# cslr_rac_cfg register map
Vendor: Texas Instruments
Peripheral module from a debugger description file.
Registers are 32-bit, access not given, reset 0x0 unless marked. A register's access mark holds for its fields unless they carry their own. Offsets are as the file gives them; lines under a group give offsets from that group; [hi:lo] are bit positions; {n}, {i} and the like mark numbered series; 'fields as' and 'values as' point back to an identical list; <NAME> marks a mode.

## RAC_CFG — Uplink Chip-Rate Decoder Co-Processor Configuration Space
{0x0+0x10*i} OCT[{i}] (i=0..767) group — Back End Output Channel Table
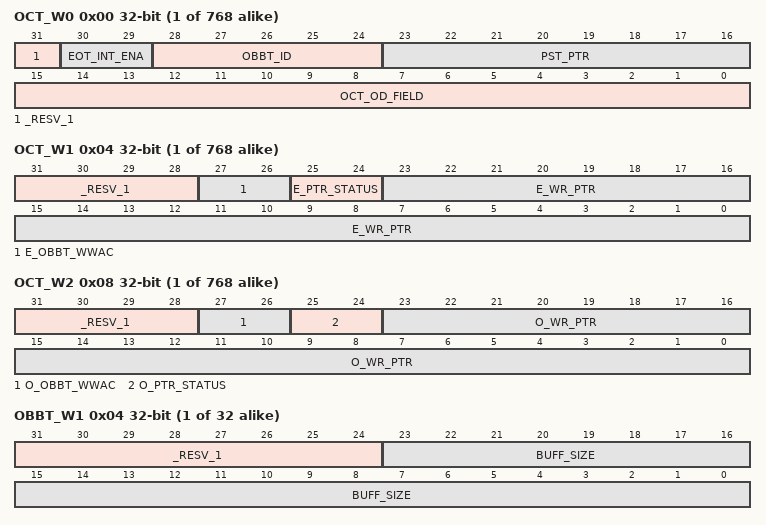
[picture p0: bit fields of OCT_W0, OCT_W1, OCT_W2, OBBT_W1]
  0x00 OCT_W0 — OCT Word 0
    [31] _RESV_1 — (access N)
    [30:29] EOT_INT_ENA rw — End of Transfer Interrupt Enable
      0=NO_INT; 1=INT_TO_DSP0; 2=INT_TO_DSP1; 3=INT_TO_DSP2
    [28:24] OBBT_ID rw — Pointer to OBBT entry
    [23:16] PST_PTR rw — Pointer to Statistics Table entry
    [15:0] OCT_OD_FIELD rw — OCT to Output Descriptor specific field
  0x04 OCT_W1 — OCT Word 1
    [31:28] _RESV_1 — (access N)
    [27:26] E_OBBT_WWAC rw — OBBT Write Wrap-Around Counter (even copy)
    [25:24] E_PTR_STATUS rw — Even Pointer Status
      0=OPEN; 1=CLOSED; 2=LOCKED
    [23:0] E_WR_PTR rw — Even Current Write Pointer
  0x08 OCT_W2 — OCT Word 2
    [31:28] _RESV_1 — (access N)
    [27:26] O_OBBT_WWAC rw — OBBT Write Wrap-Around Counter (odd copy)
    [25:24] O_PTR_STATUS rw — Odd Pointer Status
      0=OPEN; 1=CLOSED; 2=LOCKED
    [23:0] O_WR_PTR rw — Odd Current Write Pointer
{0x0+0x20*i} OBBT[{i}] (i=0..31) group — Back End Output Block Buffer Table
  0x00 OBBT_W0 rw — OBBT Word 0
    [31:0] START_AD — Start Address for the circular buffer
  0x04 OBBT_W1 — OBBT Word 1
    [31:24] _RESV_1 — (access N)
    [23:0] BUFF_SIZE rw — Circular Buffer Size
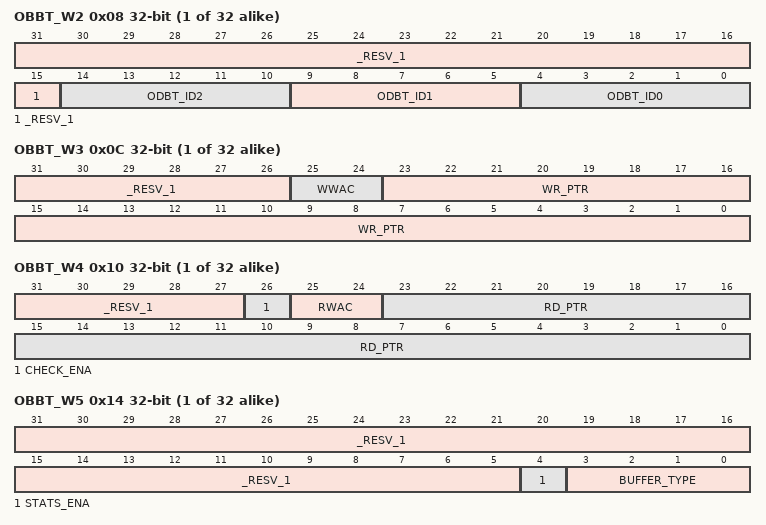
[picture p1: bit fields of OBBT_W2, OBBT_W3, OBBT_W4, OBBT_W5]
  0x08 OBBT_W2 — OBBT Word 2
    [31:15] _RESV_1 — (access N)
    [14:10] ODBT_ID2 rw — ODBT entry ID2
    [9:5] ODBT_ID1 rw — ODBT entry ID1
    [4:0] ODBT_ID0 rw — ODBT entry ID0
  0x0C OBBT_W3 — OBBT Word 3
    [31:26] _RESV_1 — (access N)
    [25:24] WWAC rw — Write Wrap-Around Counter
    [23:0] WR_PTR rw — Current Write Pointer
  0x10 OBBT_W4 — OBBT Word 4
    [31:27] _RESV_1 — (access N)
    [26] CHECK_ENA rw — Check pointers Enable Flag
      0=DISABLE; 1=ENABLE
    [25:24] RWAC rw — Read Wrap-Around Counter
    [23:0] RD_PTR rw — Current Read Pointer
  0x14 OBBT_W5 — OBBT Word 5
    [31:5] _RESV_1 — (access N)
    [4] STATS_ENA rw — Statistics Enable Flag
      0=DISABLE; 1=ENABLE
    [3:0] BUFFER_TYPE rw
{0x0+0x10*i} ODBT[{i}] (i=0..31) group — Back End Output Descriptor Buffer Table
  0x00 ODBT_W0 rw — ODBT Word 0
    [31:0] START_AD — Start Address for the circular buffer
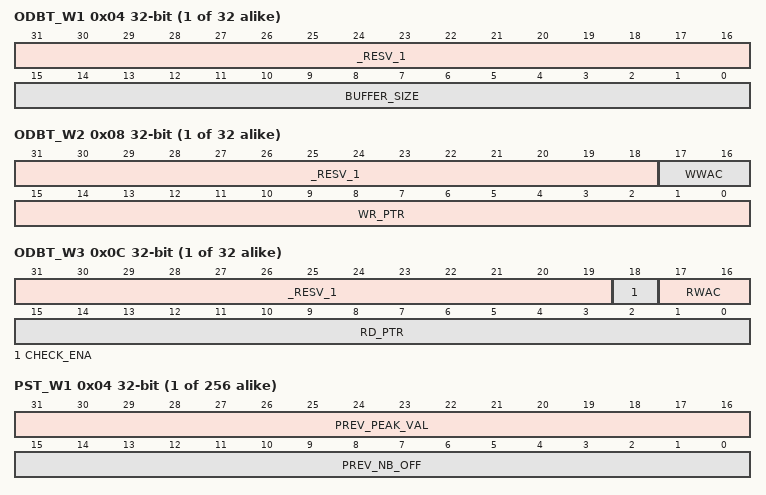
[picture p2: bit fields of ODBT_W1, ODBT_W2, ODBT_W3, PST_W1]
  0x04 ODBT_W1 — ODBT Word 1
    [31:16] _RESV_1 — (access N)
    [15:0] BUFFER_SIZE rw — Circular Buffer Size
  0x08 ODBT_W2 — ODBT Word 2
    [31:18] _RESV_1 — (access N)
    [17:16] WWAC rw — Write Wrap-Around Counter
    [15:0] WR_PTR rw — Current Write Pointer
  0x0C ODBT_W3 — ODBT Word 3
    [31:19] _RESV_1 — (access N)
    [18] CHECK_ENA rw — Check pointers Enable Flag
      0=DISABLE; 1=ENABLE
    [17:16] RWAC rw — Read Wrap-Around Counter
    [15:0] RD_PTR rw — Current Read Pointer
{0x0+0x10*i} PST[{i}] (i=0..255) group — Back End Statistics Table
  0x00 PST_W0 rw — PST Word 0
    [31:0] PREV_SUM — Previous sum
  0x04 PST_W1 rw — PST Word 1
    [31:16] PREV_PEAK_VAL — Previous offset value for highest peak
    [15:0] PREV_NB_OFF — Previous number of summed offsets
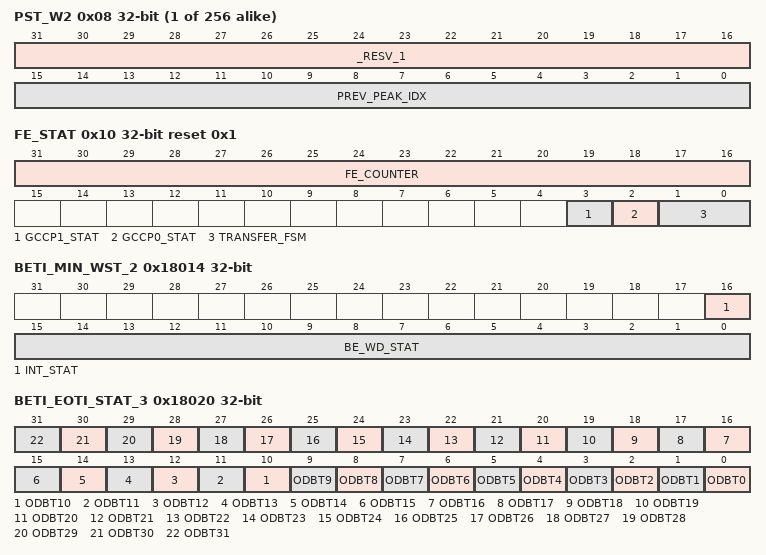
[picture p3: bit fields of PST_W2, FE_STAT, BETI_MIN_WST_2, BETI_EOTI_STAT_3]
  0x08 PST_W2 — PST Word 2
    [31:16] _RESV_1 — (access N)
    [15:0] PREV_PEAK_IDX rw — Previous offset index for highest peak
0x00 FE_PID — Front End Peripheral ID Register
0x04 FE_ENA — Front End Enable Register
  [0] ENABLE rw — Enable bit
    0=DISABLE; 1=ENABLE
0x08 FE_ID_DEPTH — GCCP Input Buffer Depth Register
  [3:0] IB_DEPTH rw — Gccp Input Buffer Depth in multiple of 32 chips
0x0C FE_MAX — Maximum Number of Cycles per Iteration Period
  [15:0] MAX_CYCLES rw — Maximum number of cycles
0x10 FE_STAT reset 0x1 — Front End Status Register
  [31:16] FE_COUNTER ro — Front End Counter current value
  [3] GCCP1_STAT ro — Gccp #1 status
    0=IDLE; 1=BUSY
  [2] GCCP0_STAT ro — Gccp #0 status
    0=IDLE; 1=BUSY
  [1:0] TRANSFER_FSM ro — Sample Transfer FSM State
    0=WAITING_TIMESTAMP; 1=RECEIVING_SAMPLES; 2=READY_TO_START; 3=START_GCCP
0x14 FE_WCFG — Front End Watch-Dog Configuration Register
  [15:0] FE_WD_CFG rw — Value that watch-dog decounter will pre-load at write into Front End FIFO
0x18 FE_WST — Front End Watch-Dog Status Register
  [15:0] FE_WD_STATUS ro — Current Value of the Watch Dog Decounter
0x1C FE_INT — Front End Watch-Dog Interrupt Status Register
  [0] INT_STATUS ro — Interrupt Status
    0=NO_INT
0x18000 BETI_ENA — Back End Transfer Interface Enable Register
  [0] ENABLE rw — Enable bit
    0=DISABLE; 1=ENABLE
0x18004 BETI_STAT — Back End Transfer Interface Status Register
  [0] STATUS rw — Status bit
    0=DISABLED; 1=ENABLED
0x18010 BETI_MIN_WCFG — Back End Minimum Activity Watch-Dog Configuration Register
  [15:0] BE_WD_CFG rw — Value to re-load each time one Output Queues becomes not empty
0x18014 BETI_MIN_WST_2 — Back End Watch-Dog Status Registers (one per GCCP)
  [16] INT_STAT ro — Interrupt Status
    0=NO_INT; 1=INT_GENERATED
  [15:0] BE_WD_STAT ro — Current Value of the decounter
0x18020 BETI_EOTI_STAT_3 ro — Back End 'End-of-Transfer' Status Registers (one per DSP core)
  [all] fields
    0=NO_NEW_OD; 1=NEW_OD
  [n] ODBT{n} (n=0..31) — Flag bit for Output Descriptor Buffer #{n}
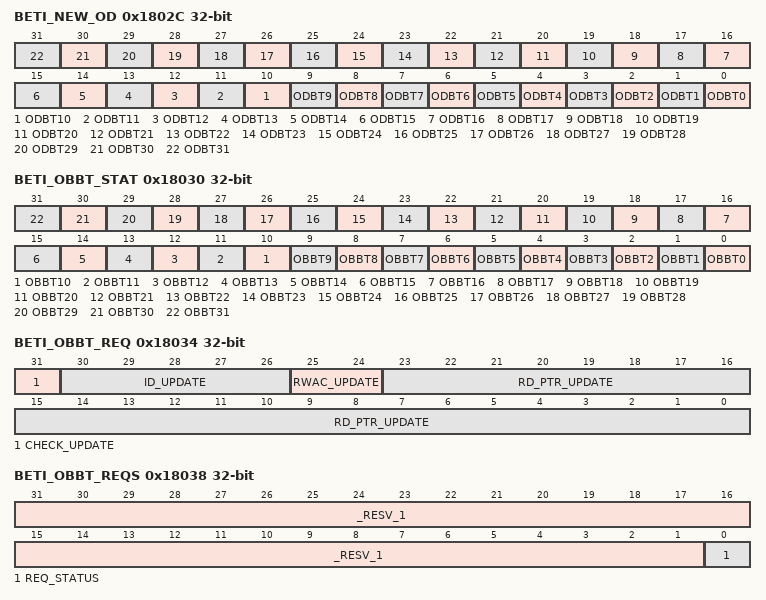
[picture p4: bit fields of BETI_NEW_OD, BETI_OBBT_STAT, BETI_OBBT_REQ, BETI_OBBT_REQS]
0x1802C BETI_NEW_OD ro — Back End 'New-OD' Status Register
  fields as BETI_EOTI_STAT_3
0x18030 BETI_OBBT_STAT ro — Back End OBBT Read Pointer Crossing Status Register
  [all] fields
    0=NO_ERROR; 1=BUFFER_IN_ERROR
  [n] OBBT{n} (n=0..31) — Read Pointer Crossing Error for Output Block Buffer #{n}
0x18034 BETI_OBBT_REQ rw — Back End OBBT Read Pointer Update Request Register
  [31] CHECK_UPDATE — Update Value for Check Flag
    0=DISABLE; 1=ENABLE
  [30:26] ID_UPDATE — Entry ID to update
  [25:24] RWAC_UPDATE — Update Value for Read Wrap-Around Counter
  [23:0] RD_PTR_UPDATE — Update Value for Read Pointer
0x18038 BETI_OBBT_REQS — Back End OBBT Read Pointer Update Status Register
  [31:1] _RESV_1 — (access N)
  [0] REQ_STATUS rw — Update Request Status
    0=IDLE; 1=PENDING
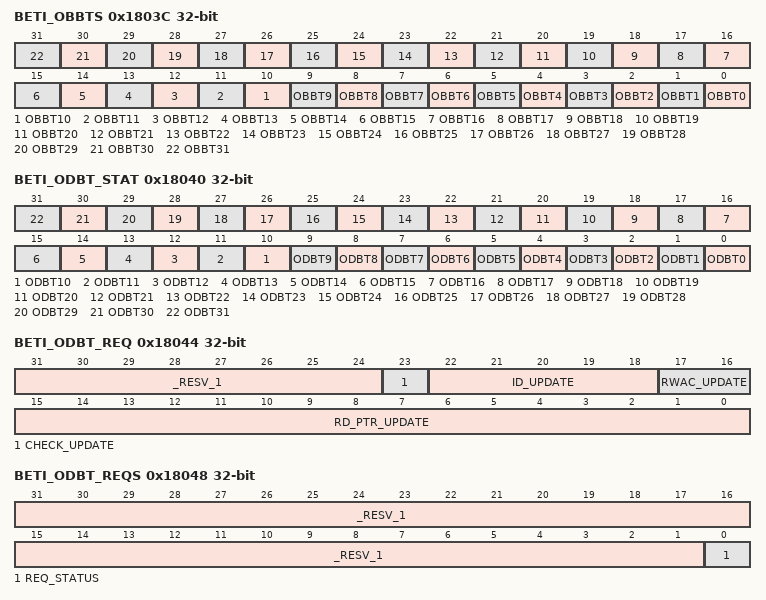
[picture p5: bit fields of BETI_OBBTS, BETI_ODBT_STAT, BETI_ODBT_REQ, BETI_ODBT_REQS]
0x1803C BETI_OBBTS ro — Back End OBBT Status Register
  [all] fields
    0=UNLOCKED; 1=LOCKED
  [n] OBBT{n} (n=0..31) — Status of Output Block Buffer #{n}
0x18040 BETI_ODBT_STAT ro — Back End ODBT Read Pointer Crossing Status Register
  [all] fields
    0=NO_ERROR; 1=BUFFER_IN_ERROR
  [n] ODBT{n} (n=0..31) — Read Pointer Crossing Error for Output Descriptor Buffer #{n}
0x18044 BETI_ODBT_REQ — Back End ODBT Read Pointer Update Request Register
  [31:24] _RESV_1 — (access N)
  [23] CHECK_UPDATE rw — Update Value for Check Flag
    0=DISABLE; 1=ENABLE
  [22:18] ID_UPDATE rw — Entry ID to update
  [17:16] RWAC_UPDATE rw — Update Value for Read Wrap-Around Counter
  [15:0] RD_PTR_UPDATE rw — Update Value for Read Pointer
0x18048 BETI_ODBT_REQS — Back End ODBT Read Pointer Update Status Register
  fields as BETI_OBBT_REQS
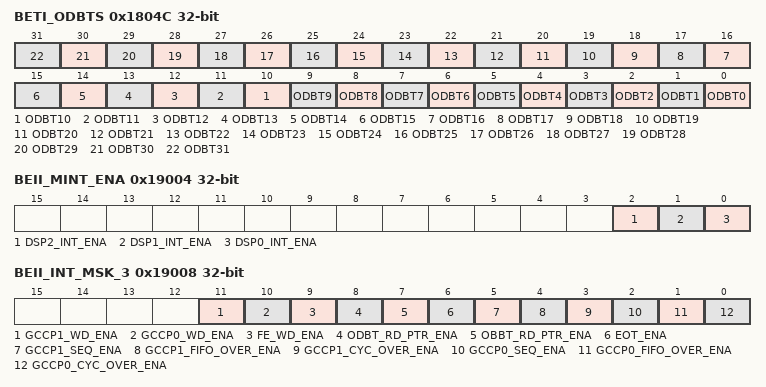
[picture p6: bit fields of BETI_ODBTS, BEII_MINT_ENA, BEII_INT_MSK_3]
0x1804C BETI_ODBTS ro — Back End ODBT Status Register
  [all] fields
    0=UNLOCKED; 1=LOCKED
  [n] ODBT{n} (n=0..31) — Status of Output Descriptor Buffer #{n}
0x19000 BEII_ENA — Back End Interrupt Interface Enable Register
  [0] ENABLE rw — Enable bit
    0=DISABLE; 1=ENABLE
0x19004 BEII_MINT_ENA — Back End Main Interrupt Enable Register
  [all] fields
    0=DISABLE; 1=ENABLE
  [2] DSP2_INT_ENA rw — Global Interrupt to DSP#2 enable
  [1] DSP1_INT_ENA rw — Global Interrupt to DSP#1 enable
  [0] DSP0_INT_ENA rw — Global Interrupt to DSP#0 enable
0x19008 BEII_INT_MSK_3 — Back End Interrupt Mask Registers
  [all] fields
    0=DISABLE; 1=ENABLE
  [11] GCCP1_WD_ENA rw — GCCP1-to-BETI minimum activity Watch-Dog enable
  [10] GCCP0_WD_ENA rw — GCCP0-to-BETI minimum activity Watch-Dog enable
  [9] FE_WD_ENA rw — Front-End Watch-Dog enable
  [8] ODBT_RD_PTR_ENA rw — BETI ODBT read pointer crossing enable
  [7] OBBT_RD_PTR_ENA rw — BETI OBBT read pointer crossing enable
  [6] EOT_ENA rw — BETI 'end-of-transfer' enable
  [5] GCCP1_SEQ_ENA rw — GCCP#1 Sequencer Idle enable
  [4] GCCP1_FIFO_OVER_ENA rw — GCCP#1 FIFO Overflow enable
  [3] GCCP1_CYC_OVER_ENA rw — GCCP#1 Cycle Overflow enable
  [2] GCCP0_SEQ_ENA rw — GCCP#0 Sequencer Idle enable
  [1] GCCP0_FIFO_OVER_ENA rw — GCCP#0 FIFO Overflow enable
  [0] GCCP0_CYC_OVER_ENA rw — GCCP#0 Cycle Overflow enable
0x1A000 CFG_TOT — Nb Access on CFG interface Register
  [15:0] TOT_ACC_NB rw — Number of total accesses for the CFG VBUS interface
0x1A004 CFG_WRIT — Nb Write Access on CFG interface Register
  [15:0] WR_ACC_NB rw — Number of write accesses for the CFG VBUS interface
0x1A008 CFG_READ — Nb Read Access on CFG interface Register
  [15:0] RD_ACC_NB rw — Number of read accesses for the CFG VBUS interface
0x1A010 SLV_TOT — Nb Access on DMA Slave Register
  [15:0] TOT_ACC_NB rw — Number of total accesses for the DMA VBUS slave interface
0x1A014 SLV_WRIT — Nb Write Access on DMA Slave Register
  [15:0] WR_ACC_NB rw — Number of write accesses for the DMA VBUS slave interface
0x1A018 SLV_READ — Nb Read Access on DMA Slave Register
  [15:0] RD_ACC_NB rw — Number of read accesses for the DMA VBUS slave interface
0x1A020 MST_TOT_LP — Nb Access on DMA Master Low Priority Register
  [15:0] TOT_ACC_NB rw — Number of total accesses for the DMA VBUS Low Priority master interface
0x1A024 MST_TOT_HP — Nb Access on DMA Master High Priority Register
  [15:0] TOT_ACC_NB rw — Number of total accesses for the DMA VBUS High Priority master interface
0x1A100 IGNORE_EMU — Emulation Mode control Register
  [0] IGNORE_EMU rw — Emulation Ignore command
    0=EMU_ON; 1=EMU_OFF
